# MIMXRT1062 register map
Vendor: nxp.com; File version: 1.0
CPU: CM7 r0p1, little endian, MPU, FPU, VTOR, 4 interrupt priority bits
Registers are 32-bit, read-write, reset 0x0 unless marked. A register's access mark holds for its fields unless they carry their own. Offsets are from the block's base; [hi:lo] are bit positions; {n}, {i} and the like mark numbered series; 'fields as' and 'values as' point back to an identical list.

## CSU — CSU registers
Base 0x400DC000; register names take the prefix CSU_
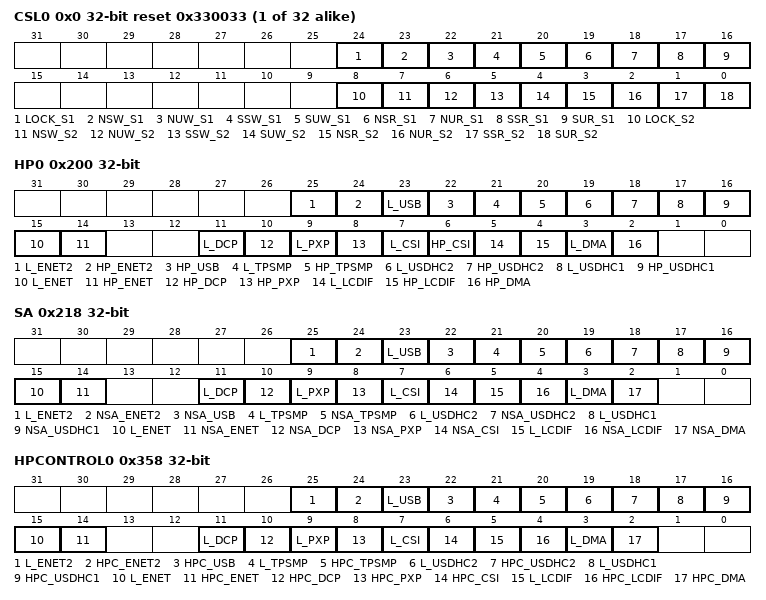
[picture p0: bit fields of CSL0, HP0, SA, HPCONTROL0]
{0x0+4i} CSL{i} (i=0..31) reset 0x330033 — Config security level register
  [24] LOCK_S1 — The lock bit corresponding to the first slave. It is written by the secure software.
    0=Not locked. The bits 16-23 can be written by the software.; 1=The bits 16-23 are locked and can't be written by the software
  [23] NSW_S1 — Non-secure supervisor write access control for the first slave
    0=The non-secure supervisor write access is disabled for the first slave; 1=The non-secure supervisor write access is enabled for the first slave
  [22] NUW_S1 — Non-secure user write access control for the first slave
    0=The non-secure user write access is disabled for the first slave; 1=The non-secure user write access is enabled for the first slave
  [21] SSW_S1 — Secure supervisor write access control for the first slave
    0=The secure supervisor write access is disabled for the first slave; 1=The secure supervisor write access is enabled for the first slave
  [20] SUW_S1 — Secure user write access control for the first slave
    0=The secure user write access is disabled for the first slave; 1=The secure user write access is enabled for the first slave
  [19] NSR_S1 — Non-secure supervisor read access control for the first slave
    0=The non-secure supervisor read access is disabled for the first slave; 1=The non-secure supervisor read access is enabled for the first slave
  [18] NUR_S1 — Non-secure user read access control for the first slave
    0=The non-secure user read access is disabled for the first slave; 1=The non-secure user read access is enabled for the first slave
  [17] SSR_S1 — Secure supervisor read access control for the first slave
    0=The secure supervisor read access is disabled for the first slave; 1=The secure supervisor read access is enabled for the first slave
  [16] SUR_S1 — Secure user read access control for the first slave
    0=The secure user read access is disabled for the first slave; 1=The secure user read access is enabled for the first slave
  [8] LOCK_S2 — The lock bit corresponding to the second slave. It is written by the secure software.
    0=Not locked. Bits 7-0 can be written by the software.; 1=Bits 7-0 are locked and cannot be written by the software
  [7] NSW_S2 — Non-secure supervisor write access control for the second slave
    0=The non-secure supervisor write access is disabled for the second slave; 1=The non-secure supervisor write access is enabled for the second slave
  [6] NUW_S2 — Non-secure user write access control for the second slave
    0=The non-secure user write access is disabled for the second slave; 1=The non-secure user write access is enabled for the second slave
  [5] SSW_S2 — Secure supervisor write access control for the second slave
    0=The secure supervisor write access is disabled for the second slave; 1=The secure supervisor write access is enabled for the second slave
  [4] SUW_S2 — Secure user write access control for the second slave
    0=The secure user write access is disabled for the second slave; 1=The secure user write access is enabled for the second slave
  [3] NSR_S2 — Non-secure supervisor read access control for the second slave
    0=The non-secure supervisor read access is disabled for the second slave; 1=The non-secure supervisor read access is enabled for the second slave
  [2] NUR_S2 — Non-secure user read access control for the second slave
    0=The non-secure user read access is disabled for the second slave; 1=The non-secure user read access is enabled for the second slave
  [1] SSR_S2 — Secure supervisor read access control for the second slave
    0=The secure supervisor read access is disabled for the second slave; 1=The secure supervisor read access is enabled for the second slave
  [0] SUR_S2 — Secure user read access control for the second slave
    0=The secure user read access is disabled for the second slave; 1=The secure user read access is enabled for the second slave
0x200 HP0
  [25] L_ENET2 — Lock bit set by the TZ software for the ENET2
    0=No lock-the adjacent (next lower) bit can be written by the software; 1=Lock-the adjacent (next lower) bit can't be written by the software
  [24] HP_ENET2 — Determines whether the register value of the corresponding HP field is passed as the hprot[1] of the ENET2
    0=The hprot1 input signal value is routed to the csu_hprot1 output for the corresponding master; 1=The HP register bit is routed to the csu_hprot1 output for the corresponding master
  [23] L_USB — Lock bit set by the TZ software for the USB
    values as L_ENET2
  [22] HP_USB — Determines whether the register value of the corresponding HP field is passed as the hprot[1] of the USB
    values as HP_ENET2
  [21] L_TPSMP — Lock bit set by the TZ software for the TPSMP
    values as L_ENET2
  [20] HP_TPSMP — Determines whether the register value of the corresponding HP field is passed as the hprot[1] of the TPSMP
    values as HP_ENET2
  [19] L_USDHC2 — Lock bit set by the TZ software for the USDHC2
    values as L_ENET2
  [18] HP_USDHC2 — Determines whether the register value of the corresponding HP field is passed as the hprot[1] of the USDHC2
    values as HP_ENET2
  [17] L_USDHC1 — Lock bit set by the TZ software for the USDHC1
    values as L_ENET2
  [16] HP_USDHC1 — Determines whether the register value of the corresponding HP field is passed as the hprot[1] of the USDHC1
    values as HP_ENET2
  [15] L_ENET — Lock bit set by the TZ software for the ENET
    values as L_ENET2
  [14] HP_ENET — Determines whether the register value of the corresponding HP field is passed as the hprot[1] of the ENET
    values as HP_ENET2
  [11] L_DCP — Lock bit set by the TZ software for the DCP
    0=No lock-the adjacent (next lower) bit can be written by the software; 1=Lock-the adjacent (next lower) bit cannot be written by the software
  [10] HP_DCP — Determines whether the register value of the corresponding HP field is passed as the hprot[1] of the DCP
    values as HP_ENET2
  [9] L_PXP — Lock bit set by the TZ software for the PXP
    values as L_ENET2
  [8] HP_PXP — Determines whether the register value of the corresponding HP field is passed as the hprot[1] of the PXP
    values as HP_ENET2
  [7] L_CSI — Lock bit set by the TZ software for the CSI
    values as L_ENET2
  [6] HP_CSI — Determines whether the register value of the corresponding HP field is passed as the hprot[1] of the CSI
    values as HP_ENET2
  [5] L_LCDIF — Lock bit set by the TZ software for the LCDIF
    values as L_ENET2
  [4] HP_LCDIF — Determines whether the register value of the corresponding HP field is passed as the hprot[1] of the LCDIF
    values as HP_ENET2
  [3] L_DMA — Lock bit set by the TZ software for the eDMA
    values as L_ENET2
  [2] HP_DMA — Determines whether the register value of the corresponding HP field is passed as the hprot[1] of the eDMA
    values as HP_ENET2
0x218 SA — Secure access register
  [25] L_ENET2 — Lock bit set by the TZ software for the ENET2
    values as HP0.L_ENET2
  [24] NSA_ENET2 — Non-secure access policy indicator bit
    0=Secure access for the corresponding type-1 master; 1=Non-secure access for the corresponding type-1 master
  [23] L_USB — Lock bit set by the TZ software for the USB
    values as HP0.L_ENET2
  [22] NSA_USB — Non-secure access policy indicator bit
    values as NSA_ENET2
  [21] L_TPSMP — Lock bit set by the TZ software for the TPSMP
    values as HP0.L_ENET2
  [20] NSA_TPSMP — Non-secure access policy indicator bit
    values as NSA_ENET2
  [19] L_USDHC2 — Lock bit set by the TZ software for the USDHC2
    values as HP0.L_ENET2
  [18] NSA_USDHC2 — Non-secure access policy indicator bit
    values as NSA_ENET2
  [17] L_USDHC1 — Lock bit set by the TZ software for the USDHC1
    values as HP0.L_ENET2
  [16] NSA_USDHC1 — Non-secure access policy indicator bit
    values as NSA_ENET2
  [15] L_ENET — Lock bit set by the TZ software for the ENET
    values as HP0.L_ENET2
  [14] NSA_ENET — Non-secure access policy indicator bit
    values as NSA_ENET2
  [11] L_DCP — Lock bit set by the TZ software for the DCP
    values as HP0.L_ENET2
  [10] NSA_DCP — Non-secure access policy indicator bit
    values as NSA_ENET2
  [9] L_PXP — Lock bit set by the TZ software for the PXP
    values as HP0.L_ENET2
  [8] NSA_PXP — Non-Secure Access Policy indicator bit
    values as NSA_ENET2
  [7] L_CSI — Lock bit set by the TZ software for the CSI
    values as HP0.L_ENET2
  [6] NSA_CSI — Non-secure access policy indicator bit
    values as NSA_ENET2
  [5] L_LCDIF — Lock bit set by the TZ software for the LCDIF
    values as HP0.L_ENET2
  [4] NSA_LCDIF — Non-secure access policy indicator bit
    values as NSA_ENET2
  [3] L_DMA — Lock bit set by the TZ software for the eDMA
    values as HP0.L_ENET2
  [2] NSA_DMA — Non-secure access policy indicator bit
    values as NSA_ENET2
0x358 HPCONTROL0
  [25] L_ENET2 — Lock bit set by the TZ software for the ENET2
    values as HP0.L_ENET2
  [24] HPC_ENET2 — Indicates the privilege/user mode for the ENET2
    0=User mode for the corresponding master; 1=Supervisor mode for the corresponding master
  [23] L_USB — Lock bit set by the TZ software for the USB.
    values as HP0.L_ENET2
  [22] HPC_USB — Indicates the privilege/user mode for the USB
    values as HPC_ENET2
  [21] L_TPSMP — Lock bit set by the TZ software for the TPSMP.
    values as HP0.L_ENET2
  [20] HPC_TPSMP — Indicates the privilege/user mode for the TPSMP
    values as HPC_ENET2
  [19] L_USDHC2 — Lock bit set by the TZ software for the USDHC2.
    values as HP0.L_ENET2
  [18] HPC_USDHC2 — Indicates the privilege/user mode for the USDHC2
    values as HPC_ENET2
  [17] L_USDHC1 — Lock bit set by the TZ software for the USDHC1
    values as HP0.L_ENET2
  [16] HPC_USDHC1 — Indicates the privilege/user mode for the USDHC1
    values as HPC_ENET2
  [15] L_ENET — Lock bit set by the TZ software for the ENET
    values as HP0.L_ENET2
  [14] HPC_ENET — Indicates the privilege/user mode for the ENET
    values as HPC_ENET2
  [11] L_DCP — Lock bit set by the TZ software for the DCP
    values as HP0.L_ENET2
  [10] HPC_DCP — Indicates the privilege/user mode for the DCP
    values as HPC_ENET2
  [9] L_PXP — Lock bit set by the TZ software for the PXP
    values as HP0.L_ENET2
  [8] HPC_PXP — Indicates the privilege/user mode for the PXP
    values as HPC_ENET2
  [7] L_CSI — Lock bit set by the TZ software for the CSI
    values as HP0.L_ENET2
  [6] HPC_CSI — Indicates the privilege/user mode for the CSI
    values as HPC_ENET2
  [5] L_LCDIF — Lock bit set by the TZ software for the LCDIF
    values as HP0.L_ENET2
  [4] HPC_LCDIF — Indicates the privilege/user mode for the LCDIF
    values as HPC_ENET2
  [3] L_DMA — Lock bit set by the TZ software for the eDMA
    values as HP0.L_ENET2
  [2] HPC_DMA — Indicates the privilege/user mode for the eDMA
    values as HPC_ENET2
